# RZV2L register map
Vendor: Renesas; Series: All Chips; File version: x.xx
Registers are 32-bit, access not given, no defined reset value unless marked. A register's access mark holds for its fields unless they carry their own. Offsets are from the block's base; [hi:lo] are bit positions; {n}, {i} and the like mark numbered series; 'fields as' and 'values as' point back to an identical list.

## GTM0
Base 0x42801000
Same registers: GTM1 0x42801400, GTM2 0x42801800
0x00 OSTMnCMP
0x04 OSTMnCNT
0x10 OSTMnTE 8-bit
  [0] OSTMnTE
0x14 OSTMnTS 8-bit
  [0] OSTMnTS
0x18 OSTMnTT 8-bit
  [0] OSTMnTT
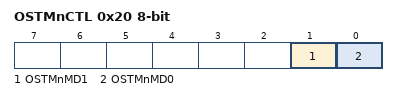
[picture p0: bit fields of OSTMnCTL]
0x20 OSTMnCTL 8-bit
  [1] OSTMnMD1, [0] OSTMnMD0

## INTC_IM33
Base 0x410B0000
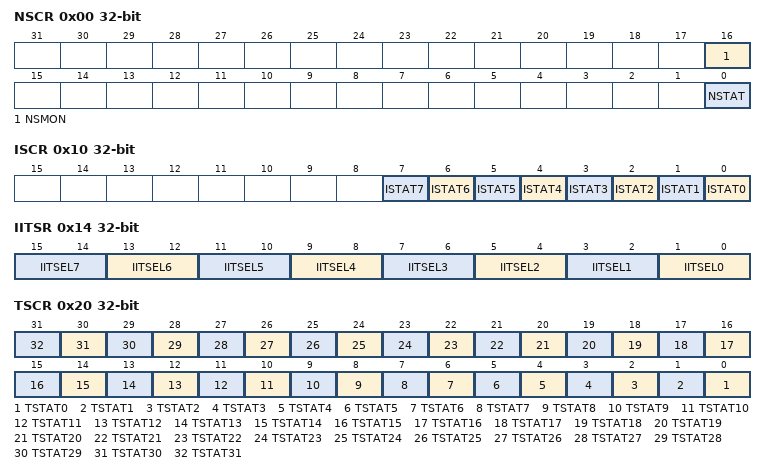
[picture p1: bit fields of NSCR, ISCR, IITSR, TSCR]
0x00 NSCR
  [16] NSMON, [0] NSTAT
0x04 NITSR
  [0] NTSEL
0x10 ISCR
  [n] ISTAT{n} (n=0..7)
0x14 IITSR
  [2n+1:2n] IITSEL{n} (n=0..7)
0x20 TSCR
  [n] TSTAT{n} (n=0..31)
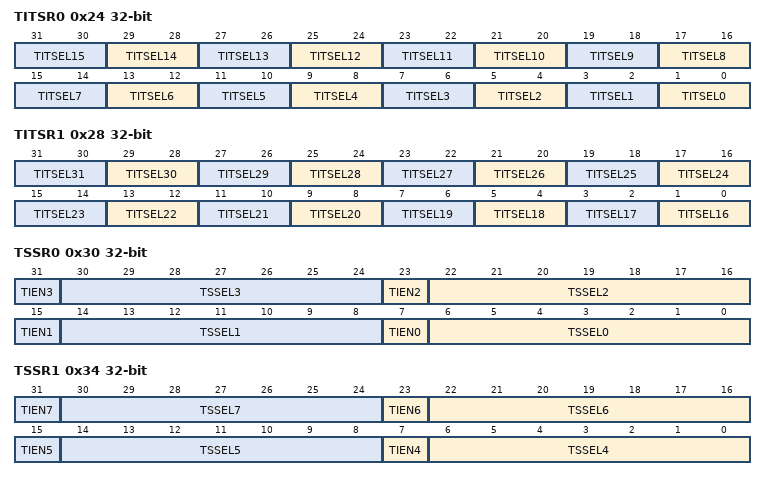
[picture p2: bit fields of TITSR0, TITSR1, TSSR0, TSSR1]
0x24 TITSR0
  [2n+1:2n] TITSEL{n} (n=0..15)
0x28 TITSR1
  [2n-31:2n-32] TITSEL{n} (n=16..31)
0x30 TSSR0
  [8n+7] TIEN{n} (n=0..3), [8n+6:8n] TSSEL{n} (n=0..3)
0x34 TSSR1
  [8n-25] TIEN{n} (n=4..7), [8n-26:8n-32] TSSEL{n} (n=4..7)
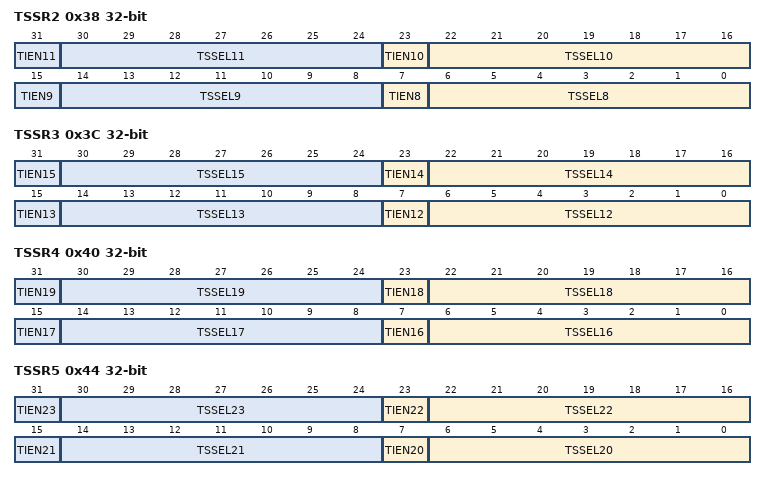
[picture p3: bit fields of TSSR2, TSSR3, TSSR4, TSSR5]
0x38 TSSR2
  [8n-57] TIEN{n} (n=8..11), [8n-58:8n-64] TSSEL{n} (n=8..11)
0x3C TSSR3
  [8n-89] TIEN{n} (n=12..15), [8n-90:8n-96] TSSEL{n} (n=12..15)
0x40 TSSR4
  [8n-121] TIEN{n} (n=16..19), [8n-122:8n-128] TSSEL{n} (n=16..19)
0x44 TSSR5
  [8n-153] TIEN{n} (n=20..23), [8n-154:8n-160] TSSEL{n} (n=20..23)
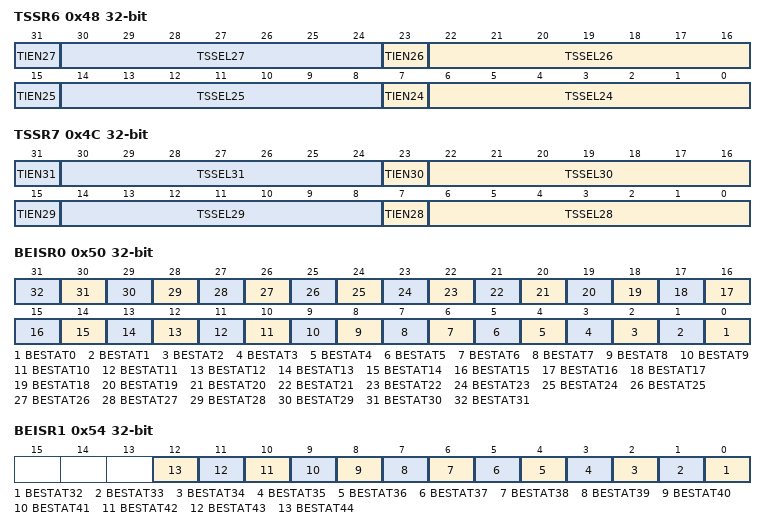
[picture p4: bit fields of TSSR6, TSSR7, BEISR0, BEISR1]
0x48 TSSR6
  [8n-185] TIEN{n} (n=24..27), [8n-186:8n-192] TSSEL{n} (n=24..27)
0x4C TSSR7
  [8n-217] TIEN{n} (n=28..31), [8n-218:8n-224] TSSEL{n} (n=28..31)
0x50 BEISR0
  [n] BESTAT{n} (n=0..31)
0x54 BEISR1
  [n-32] BESTAT{n} (n=32..44)
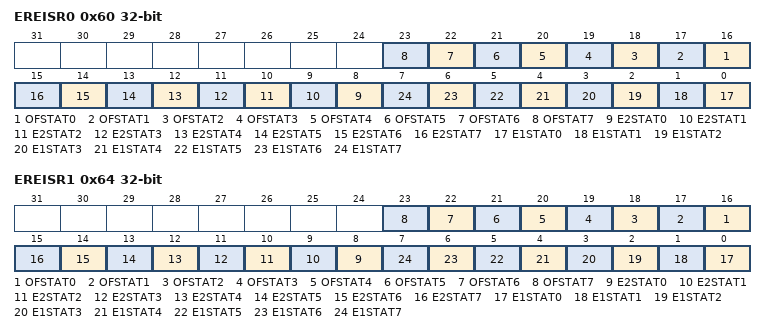
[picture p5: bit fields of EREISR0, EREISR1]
0x60 EREISR0
  [n+16] OFSTAT{n} (n=0..7), [n+8] E2STAT{n} (n=0..7), [n] E1STAT{n} (n=0..7)
0x64 EREISR1
  fields as EREISR0

## MHU0
Base 0x40400000
Same registers: MHU1 0x40400020, MHU2 0x40400040, MHU3 0x40400060, MHU4 0x40400080, MHU5 0x404000A0
0x00 MSG_INT_STSn
  [0] STAT
0x04 MSG_INT_SETn
  [0] SET
0x08 MSG_INT_CLRn
  [0] CLEAR
0x10 RSP_INT_STSn
  [0] STAT
0x14 RSP_INT_SETn
  [0] SET
0x18 RSP_INT_CLRn
  [0] CLEAR

## MHU_SWINT0
Base 0x40400800
Same registers: MHU_SWINT1 0x40400810, MHU_SWINT2 0x40400820, MHU_SWINT3 0x40400830
0x00 SW_INT_STSn
  [0] STAT
0x04 SW_INT_SETn
  [0] SET
0x08 SW_INT_CLRn
  [0] CLEAR

## POEGA
Base 0x40048800
Same registers: POEGB 0x40048C00, POEGC 0x40049000, POEGD 0x40049400
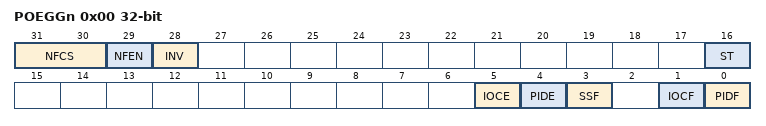
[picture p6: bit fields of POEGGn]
0x00 POEGGn
  [31:30] NFCS, [29] NFEN, [28] INV, [16] ST, [5] IOCE, [4] PIDE, [3] SSF, [1] IOCF, [0] PIDF

## RIIC0
Base 0x40058000
Same registers: RIIC1 0x40058400, RIIC2 0x40058800, RIIC3 0x40058C00
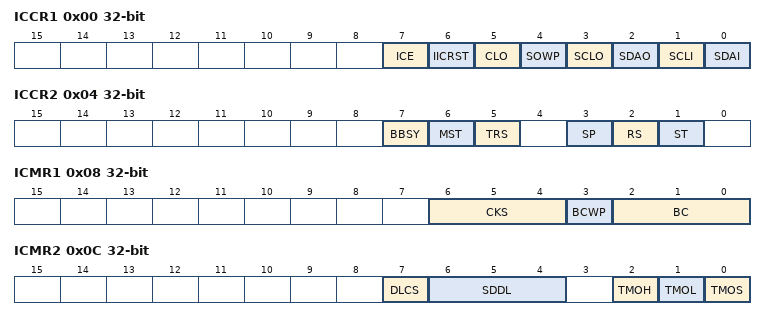
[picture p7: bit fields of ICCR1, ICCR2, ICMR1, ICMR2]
0x00 ICCR1
  [7] ICE, [6] IICRST, [5] CLO, [4] SOWP, [3] SCLO, [2] SDAO, [1] SCLI, [0] SDAI
0x04 ICCR2
  [7] BBSY, [6] MST, [5] TRS, [3] SP, [2] RS, [1] ST
0x08 ICMR1
  [6:4] CKS, [3] BCWP, [2:0] BC
0x0C ICMR2
  [7] DLCS, [6:4] SDDL, [2] TMOH, [1] TMOL, [0] TMOS
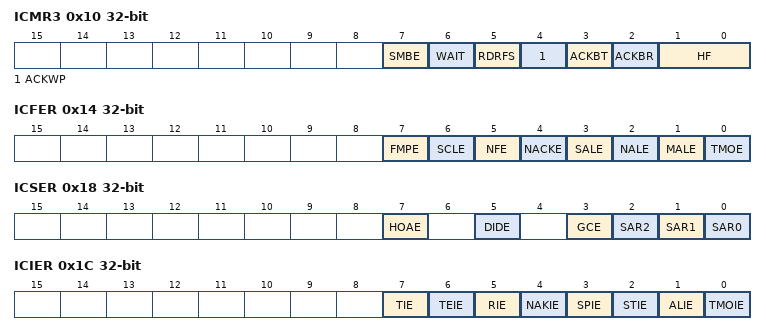
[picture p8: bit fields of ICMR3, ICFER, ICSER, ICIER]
0x10 ICMR3
  [7] SMBE, [6] WAIT, [5] RDRFS, [4] ACKWP, [3] ACKBT, [2] ACKBR, [1:0] HF
0x14 ICFER
  [7] FMPE, [6] SCLE, [5] NFE, [4] NACKE, [3] SALE, [2] NALE, [1] MALE, [0] TMOE
0x18 ICSER
  [7] HOAE, [5] DIDE, [3] GCE, [2] SAR2, [1] SAR1, [0] SAR0
0x1C ICIER
  [7] TIE, [6] TEIE, [5] RIE, [4] NAKIE, [3] SPIE, [2] STIE, [1] ALIE, [0] TMOIE
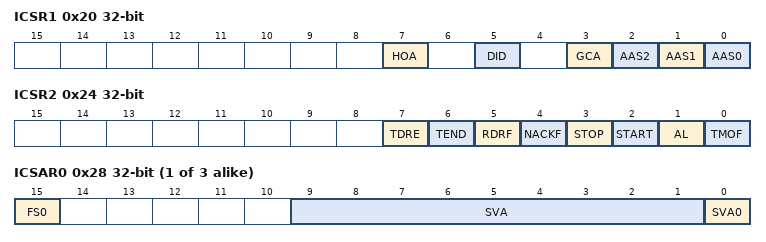
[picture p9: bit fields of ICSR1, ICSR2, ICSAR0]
0x20 ICSR1
  [7] HOA, [5] DID, [3] GCA, [2] AAS2, [1] AAS1, [0] AAS0
0x24 ICSR2
  [7] TDRE, [6] TEND, [5] RDRF, [4] NACKF, [3] STOP, [2] START, [1] AL, [0] TMOF
{0x28+4i} ICSAR{i} (i=0..2)
  [15] FS{i}, [9:1] SVA, [0] SVA0
0x34 ICBRL
  [4:0] BRL
0x38 ICBRH
  [4:0] BRH
0x3C ICDRT
  [7:0] DRT
0x40 ICDRR
  [7:0] DRR

## RSPI0
Base 0x4004AC00
Same registers: RSPI1 0x4004B000, RSPI2 0x4004B400
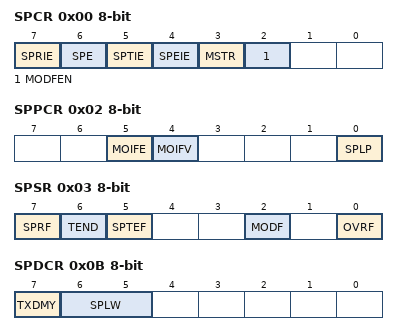
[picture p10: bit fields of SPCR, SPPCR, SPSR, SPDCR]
0x00 SPCR 8-bit
  [7] SPRIE, [6] SPE, [5] SPTIE, [4] SPEIE, [3] MSTR, [2] MODFEN
0x01 SSLP 8-bit
  [0] SSL0P
0x02 SPPCR 8-bit
  [5] MOIFE, [4] MOIFV, [0] SPLP
0x03 SPSR 8-bit
  [7] SPRF, [6] TEND, [5] SPTEF, [2] MODF, [0] OVRF
0x04 SPDR
  [31:0] SPD
0x08 SPSCR 8-bit
  [1:0] SPSLN
0x09 SPSSR 8-bit
  [1:0] SPCP
0x0A SPBR 8-bit
  [7:0] SPR
0x0B SPDCR 8-bit
  [7] TXDMY, [6:5] SPLW
0x0C SPCKD 8-bit
  [2:0] SCKDL
0x0D SSLND 8-bit
  [2:0] SLNDL
0x0E SPND 8-bit
  [2:0] SPNDL
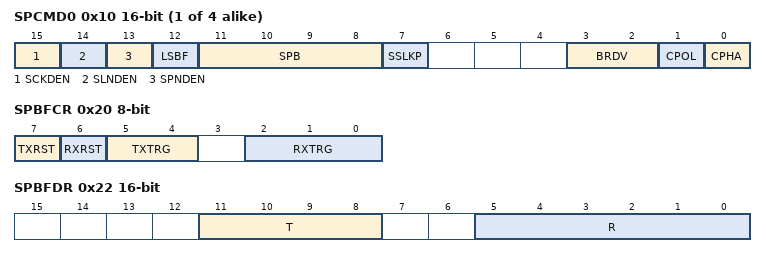
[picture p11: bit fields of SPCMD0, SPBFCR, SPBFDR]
{0x10+2i} SPCMD{i} 16-bit (i=0..3)
  [15] SCKDEN, [14] SLNDEN, [13] SPNDEN, [12] LSBF, [11:8] SPB, [7] SSLKP, [3:2] BRDV, [1] CPOL, [0] CPHA
0x20 SPBFCR 8-bit
  [7] TXRST, [6] RXRST, [5:4] TXTRG, [2:0] RXTRG
0x22 SPBFDR 16-bit
  [11:8] T, [5:0] R

## SCIFA0
Base 0x4004B800
Same registers: SCIFA1 0x4004BC00, SCIFA2 0x4004C000, SCIFA3 0x4004C400, SCIFA4 0x4004C800
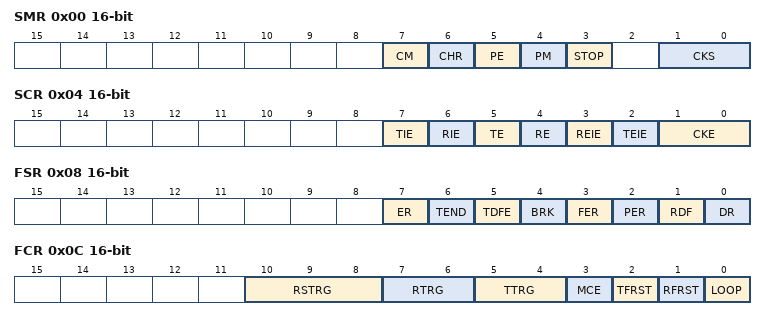
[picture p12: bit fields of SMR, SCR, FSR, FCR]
0x00 SMR 16-bit
  [7] CM, [6] CHR, [5] PE, [4] PM, [3] STOP, [1:0] CKS
0x02 MDDR 8-bit
0x02 BRR 8-bit
0x04 SCR 16-bit
  [7] TIE, [6] RIE, [5] TE, [4] RE, [3] REIE, [2] TEIE, [1:0] CKE
0x06 FTDR 8-bit
0x08 FSR 16-bit
  [7] ER, [6] TEND, [5] TDFE, [4] BRK, [3] FER, [2] PER, [1] RDF, [0] DR
0x0A FRDR 8-bit
0x0C FCR 16-bit
  [10:8] RSTRG, [7:6] RTRG, [5:4] TTRG, [3] MCE, [2] TFRST, [1] RFRST, [0] LOOP
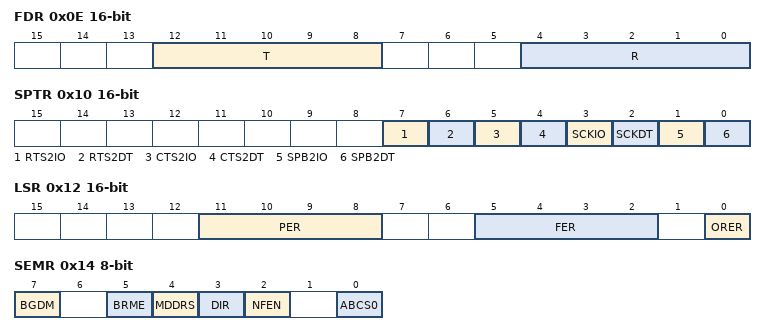
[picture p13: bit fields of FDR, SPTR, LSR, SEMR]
0x0E FDR 16-bit
  [12:8] T, [4:0] R
0x10 SPTR 16-bit
  [7] RTS2IO, [6] RTS2DT, [5] CTS2IO, [4] CTS2DT, [3] SCKIO, [2] SCKDT, [1] SPB2IO, [0] SPB2DT
0x12 LSR 16-bit
  [11:8] PER, [5:2] FER, [0] ORER
0x14 SEMR 8-bit
  [7] BGDM, [5] BRME, [4] MDDRS, [3] DIR, [2] NFEN, [0] ABCS0
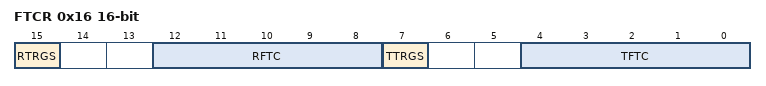
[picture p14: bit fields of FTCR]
0x16 FTCR 16-bit
  [15] RTRGS, [12:8] RFTC, [7] TTRGS, [4:0] TFTC

## SPIBSC
Base 0x40060000
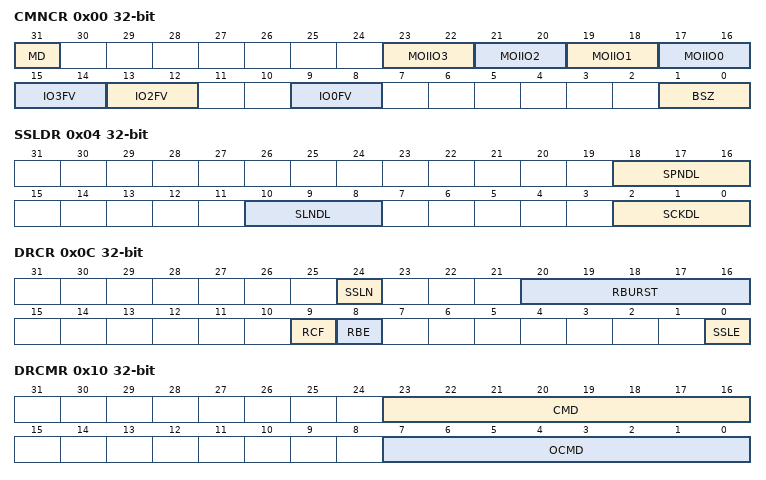
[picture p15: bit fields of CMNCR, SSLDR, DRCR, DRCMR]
0x00 CMNCR
  [31] MD, [2n+17:2n+16] MOIIO{n} (n=0..3), [15:14] IO3FV, [13:12] IO2FV, [9:8] IO0FV, [1:0] BSZ
0x04 SSLDR
  [18:16] SPNDL, [10:8] SLNDL, [2:0] SCKDL
0x0C DRCR
  [24] SSLN, [20:16] RBURST, [9] RCF, [8] RBE, [0] SSLE
0x10 DRCMR
  [23:16] CMD, [7:0] OCMD
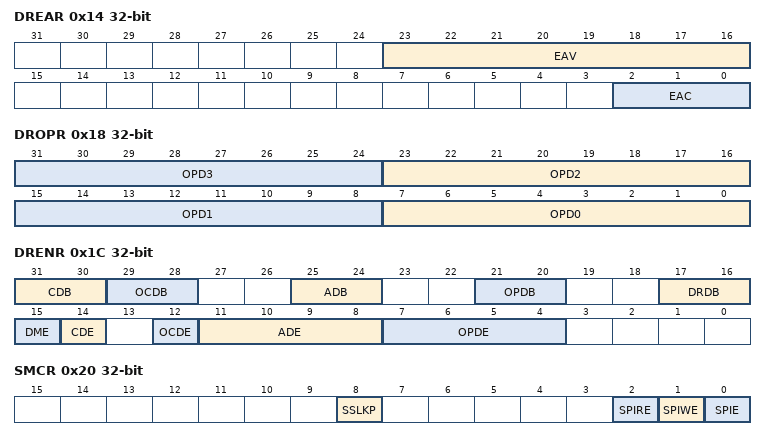
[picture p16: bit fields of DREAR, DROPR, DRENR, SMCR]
0x14 DREAR
  [23:16] EAV, [2:0] EAC
0x18 DROPR
  [8n+7:8n] OPD{n} (n=0..3)
0x1C DRENR
  [31:30] CDB, [29:28] OCDB, [25:24] ADB, [21:20] OPDB, [17:16] DRDB, [15] DME, [14] CDE, [12] OCDE, [11:8] ADE, [7:4] OPDE
0x20 SMCR
  [8] SSLKP, [2] SPIRE, [1] SPIWE, [0] SPIE
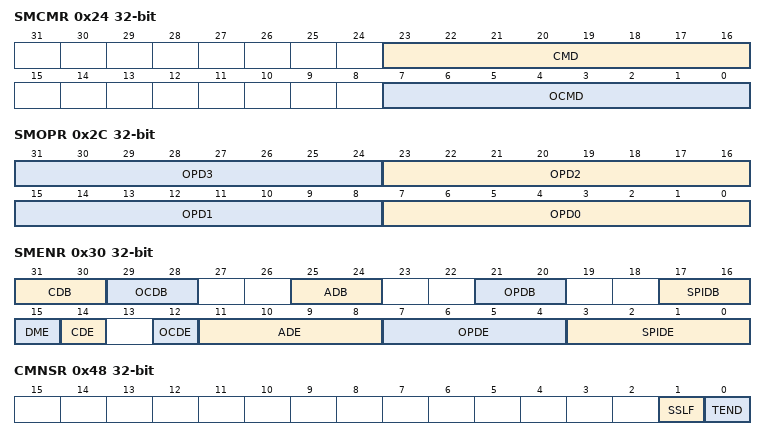
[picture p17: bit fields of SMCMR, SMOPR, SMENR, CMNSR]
0x24 SMCMR
  [23:16] CMD, [7:0] OCMD
0x28 SMADR
  [31:0] ADR
0x2C SMOPR
  [8n+7:8n] OPD{n} (n=0..3)
0x30 SMENR
  [31:30] CDB, [29:28] OCDB, [25:24] ADB, [21:20] OPDB, [17:16] SPIDB, [15] DME, [14] CDE, [12] OCDE, [11:8] ADE, [7:4] OPDE, [3:0] SPIDE
0x38 SMRDR0
  [31:0] RDATA0
0x3C SMRDR1
  [31:0] RDATA1
0x40 SMWDR0
  [31:0] WDATA0
0x44 SMWDR1
  [31:0] WDATA1
0x48 CMNSR
  [1] SSLF, [0] TEND
0x58 DRDMCR
  [4:0] DMCYC
0x5C DRDRENR
  [14:12] HYPE, [8] ADDRE, [4] OPDRE, [0] DRDRE
0x60 SMDMCR
  [4:0] DMCYC
0x64 SMDRENR
  [14:12] HYPE, [8] ADDRE, [4] OPDRE, [0] SPIDRE
0x70 PHYADJ1
  [31:0] ADJ1
0x74 PHYADJ2
  [31:0] ADJ2
0x7C PHYCNT
  [31] CAL, [30] ALT_ALIGN, [23:22] OCTA, [21] EXDS, [20] OCT, [18] HS, [17:16] CKSEL, [4] WBUF2, [2] WBUF, [1:0] PHYMEM
0x80 PHYOFFSET1
  [29:28] DDRTMG
0x84 PHYOFFSET2
  [10:8] OCTTMG
0x88 PHYINT
  [26] RSTEN, [25] WPEN, [24] INTEN, [2] RSTVAL, [1] WPVAL, [0] INT

## WDT0
Base 0x42800800
Same registers: WDT2 0x42800400, WDT1 0x42800C00
0x00 WDTCNT
  [0] WDTEN
0x04 WDTSET
  [31:20] WDTTIME
0x08 WDTTIM
  [31:0] CRTTIME
0x0C WDTINT
  [0] INTDISP
0x10 PECR
0x14 PEEN
  [0] PEEN
0x18 PESR
0x1C PEER
0x20 PEPO
